# ATmega64C1 register map
Vendor: Atmel; File version: 1.0
CPU: other r0p0, little endian, no MPU, no FPU, 4 interrupt priority bits
Registers are 8-bit, read-write, reset 0x0 unless marked. A register's access mark holds for its fields unless they carry their own. Offsets are from the block's base; [hi:lo] are bit positions; {n}, {i} and the like mark numbered series.

## LINUART — Local Interconnect Network
Base 0x000000C8
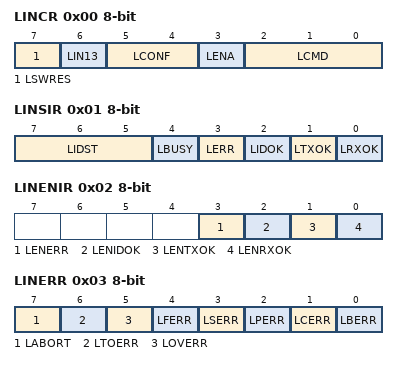
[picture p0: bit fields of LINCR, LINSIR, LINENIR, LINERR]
0x00 LINCR — LIN Control Register
  [7] LSWRES — Software Reset
  [6] LIN13 — LIN Standard
  [5:4] LCONF — LIN Configuration bits
  [3] LENA — LIN or UART Enable
  [2:0] LCMD — LIN Command and Mode bits
0x01 LINSIR — LIN Status and Interrupt Register
  [7:5] LIDST — Identifier Status bits
  [4] LBUSY — Busy Signal
  [3] LERR — Error Interrupt
  [2] LIDOK — Identifier Interrupt
  [1] LTXOK — Transmit Performed Interrupt
  [0] LRXOK — Receive Performed Interrupt
0x02 LINENIR — LIN Enable Interrupt Register
  [3] LENERR — Enable Error Interrupt
  [2] LENIDOK — Enable Identifier Interrupt
  [1] LENTXOK — Enable Transmit Performed Interrupt
  [0] LENRXOK — Enable Receive Performed Interrupt
0x03 LINERR — LIN Error Register
  [7] LABORT — Abort Flag
  [6] LTOERR — Frame Time Out Error Flag
  [5] LOVERR — Overrun Error Flag
  [4] LFERR — Framing Error Flag
  [3] LSERR — Synchronization Error Flag
  [2] LPERR — Parity Error Flag
  [1] LCERR — Checksum Error Flag
  [0] LBERR — Bit Error Flag
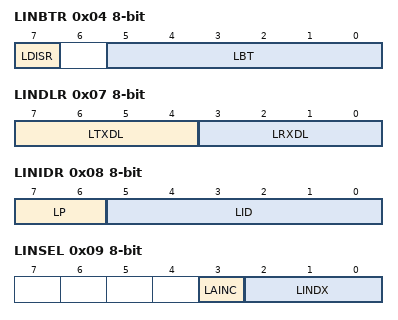
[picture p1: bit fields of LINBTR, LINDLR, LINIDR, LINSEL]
0x04 LINBTR — LIN Bit Timing Register
  [7] LDISR — Disable Bit Timing Resynchronization
  [5:0] LBT — LIN Bit Timing bits
0x05 LINBRRL — LIN Baud Rate Low Register
  [7:0] LDIV
0x06 LINBRRH — LIN Baud Rate High Register
  [3:0] LDIV
0x07 LINDLR — LIN Data Length Register
  [7:4] LTXDL — LIN Transmit Data Length bits
  [3:0] LRXDL — LIN Receive Data Length bits
0x08 LINIDR — LIN Identifier Register
  [7:6] LP — Parity bits
  [5:0] LID — Identifier bit 5 or Data Length bits
0x09 LINSEL — LIN Data Buffer Selection Register
  [3] LAINC — Auto Increment of Data Buffer Index (Active Low)
  [2:0] LINDX — FIFO LIN Data Buffer Index bits
0x0A LINDAT — LIN Data Register
  [7:0] LDATA

## LOCKBIT — Lockbits
Base 0x00000000
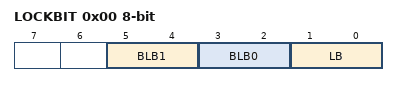
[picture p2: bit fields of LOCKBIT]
0x00 LOCKBIT
  [5:4] BLB1 — Boot Loader Protection Mode
    0=LPM_SPM_DISABLE (LPM and SPM prohibited in Boot Section); 1=LPM_DISABLE (LPM prohibited in Boot Section); 2=SPM_DISABLE (SPM prohibited in Boot Section); 3=NO_LOCK (No lock on SPM and LPM in Boot Section)
  [3:2] BLB0 — Boot Loader Protection Mode
    0=LPM_SPM_DISABLE (LPM and SPM prohibited in Application Section); 1=LPM_DISABLE (LPM prohibited in Application Section); 2=SPM_DISABLE (SPM prohibited in Application Section); 3=NO_LOCK (No lock on SPM and LPM in Application Section)
  [1:0] LB — Memory Lock
    0=PROG_VER_DISABLED (Further programming and verification disabled); 2=PROG_DISABLED (Further programming disabled); 3=NO_LOCK (No memory lock features enabled)

## PORTB — I/O Port
Base 0x00000023
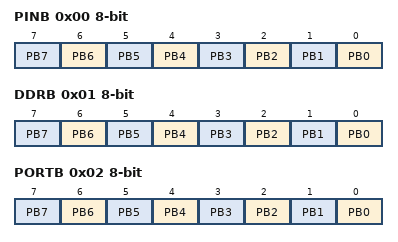
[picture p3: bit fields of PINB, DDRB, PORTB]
0x00 PINB — Port B Input Pins
  [n] PB{n} (n=0..7) — Pin B{n}
0x01 DDRB — Port B Data Direction Register
  [n] PB{n} (n=0..7) — Pin B{n}
0x02 PORTB — Port B Data Register
  [n] PB{n} (n=0..7) — Pin B{n}

## PORTC — I/O Port
Base 0x00000026
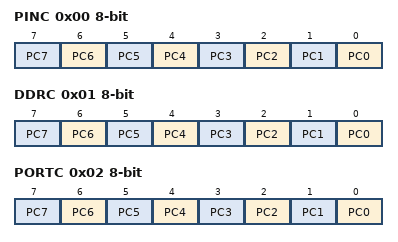
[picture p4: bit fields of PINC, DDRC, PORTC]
0x00 PINC — Port C Input Pins
  [n] PC{n} (n=0..7) — Pin C{n}
0x01 DDRC — Port C Data Direction Register
  [n] PC{n} (n=0..7) — Pin C{n}
0x02 PORTC — Port C Data Register
  [n] PC{n} (n=0..7) — Pin C{n}

## PORTD — I/O Port
Base 0x00000029
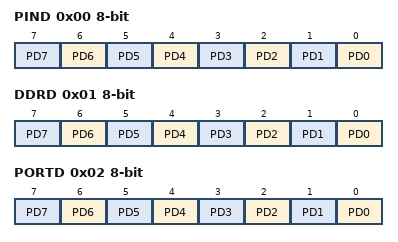
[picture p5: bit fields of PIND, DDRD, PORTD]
0x00 PIND — Port D Input Pins
  [n] PD{n} (n=0..7) — Pin D{n}
0x01 DDRD — Port D Data Direction Register
  [n] PD{n} (n=0..7) — Pin D{n}
0x02 PORTD — Port D Data Register
  [n] PD{n} (n=0..7) — Pin D{n}

## PORTE — I/O Port
Base 0x0000002C
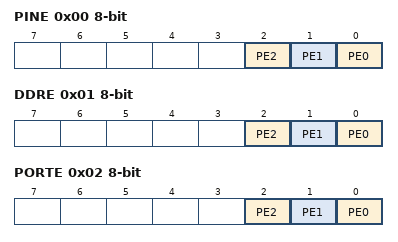
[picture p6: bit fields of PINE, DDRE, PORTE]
0x00 PINE — Port E Input Pins
  [2] PE2 — Pin E2
  [1] PE1 — Pin E1
  [0] PE0 — Pin E0
0x01 DDRE — Port E Data Direction Register
  [2] PE2 — Pin E2
  [1] PE1 — Pin E1
  [0] PE0 — Pin E0
0x02 PORTE — Port E Data Register
  [2] PE2 — Pin E2
  [1] PE1 — Pin E1
  [0] PE0 — Pin E0
